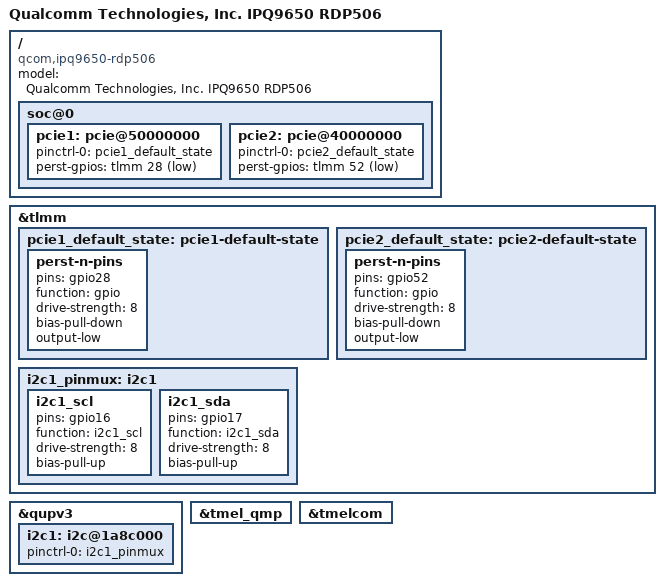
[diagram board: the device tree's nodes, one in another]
// SPDX-License-Identifier: GPL-2.0-only
/*
 * Copyright (c) Qualcomm Technologies, Inc. and/or its subsidiaries.
 */

/dts-v1/;

#include "ipq9650-u-boot.dtsi"

/ {
	model = "Qualcomm Technologies, Inc. IPQ9650 RDP506";
	compatible = "qcom,ipq9650-rdp506", "qcom,ipq9650";

	soc@0 {
		pcie1: pcie@50000000 {
			pinctrl-0 = <&pcie1_default_state>;
			pinctrl-names = "default";
			perst-gpios = <&tlmm 28 GPIO_ACTIVE_LOW>;
			status = "okay";
		};

		pcie2: pcie@40000000 {
			pinctrl-0 = <&pcie2_default_state>;
			pinctrl-names = "default";
			perst-gpios = <&tlmm 52 GPIO_ACTIVE_LOW>;
			status = "okay";
		};
	};
};

&tlmm {
	pcie1_default_state: pcie1-default-state {
		perst-n-pins {
			pins = "gpio28";
			function = "gpio";
			drive-strength = <8>;
			bias-pull-down;
			output-low;
		};
	};

	pcie2_default_state: pcie2-default-state {
		perst-n-pins {
			pins = "gpio52";
			function = "gpio";
			drive-strength = <8>;
			bias-pull-down;
			output-low;
		};
	};

	i2c1_pinmux: i2c1 {
		i2c1_scl {
			pins = "gpio16";
			function = "i2c1_scl";
			drive-strength = <8>;
			bias-pull-up;
		};

		i2c1_sda {
			pins = "gpio17";
			function = "i2c1_sda";
			drive-strength = <8>;
			bias-pull-up;
		};
	};
};

&qupv3 {
	i2c1: i2c@1a8c000 {
		pinctrl-0 = <&i2c1_pinmux>;
		pinctrl-names = "default";
		status = "okay";
	};
};

&tmel_qmp {
	status = "okay";
};

&tmelcom {
	status = "okay";
};
